# STM32L072xx register map
File version: 1.0
Registers are 32-bit, read-write, reset 0x0 unless marked. A register's access mark holds for its fields unless they carry their own. Offsets are from the block's base; [hi:lo] are bit positions.

## PWR — Power Control
Base 0x40007000
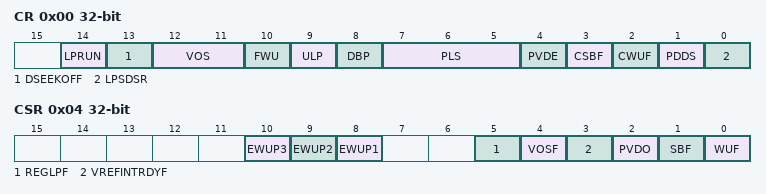
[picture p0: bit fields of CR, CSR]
0x00 CR — PWR power control register
  [14] LPRUN — Low power run mode
  [13] DSEEKOFF — Deep Sleep mode with EEPROM kept Off
  [12:11] VOS — VOS[1:0] bits (Voltage scaling range selection)
    1=SCALE1 (1.8V (range 1)); 2=SCALE2 (1.5V (range 2)); 3=SCALE3 (1.2V (range 3))
  [10] FWU — Fast wakeup
  [9] ULP — Ultra Low Power mode
  [8] DBP — Disable Backup Domain write protection
  [7:5] PLS — PLS[2:0] bits (PVD Level Selection)
    0=PVDLEVEL_0 (Voltage threshold detected by PVD 1.9 V); 1=PVDLEVEL_1 (Voltage threshold detected by PVD 2.1 V); 2=PVDLEVEL_2 (Voltage threshold detected by PVD 2.3 V); 3=PVDLEVEL_3 (Voltage threshold detected by PVD 2.5 V); 4=PVDLEVEL_4 (Voltage threshold detected by PVD 2.7 V); 5=PVDLEVEL_5 (Voltage threshold detected by PVD 2.9 V); 6=PVDLEVEL_6 (Voltage threshold detected by PVD 3.1 V); 7=PVDLEVEL_7 (External input analog voltage (Compare internally to VREFINT))
  [4] PVDE — Power Voltage Detector Enable
  [3] CSBF — Clear Standby Flag
  [2] CWUF — Clear Wakeup Flag
  [1] PDDS — Power Down Deepsleep
    0=STOP (Enter Stop mode when the CPU enters deepsleep); 1=STANDBY (Enter Standby mode when the CPU enters deepsleep)
  [0] LPSDSR — Low-power deepsleep/sleep/low power run
    0=MAIN (Voltage regulator in main mode during deepsleep/sleep/low-power run mode); 1=LOW_POWER (Voltage regulator in low-power mode during deepsleep/sleep/low-power run mode)
0x04 CSR — PWR power control/status register
  [10] EWUP3 — Enable WKUP pin 3
  [9] EWUP2 — Enable WKUP pin 2
  [8] EWUP1 — Enable WKUP pin 1
  [5] REGLPF — Regulator LP flag
  [4] VOSF — Voltage Scaling select flag
  [3] VREFINTRDYF — Internal voltage reference (VREFINT) ready flag
  [2] PVDO — PVD Output
  [1] SBF — Standby Flag
  [0] WUF — Wakeup Flag

## DAC — Digital to Analog Converter
Base 0x40007400
Same registers: DAC1 0x40007400 (alternate view of DAC)
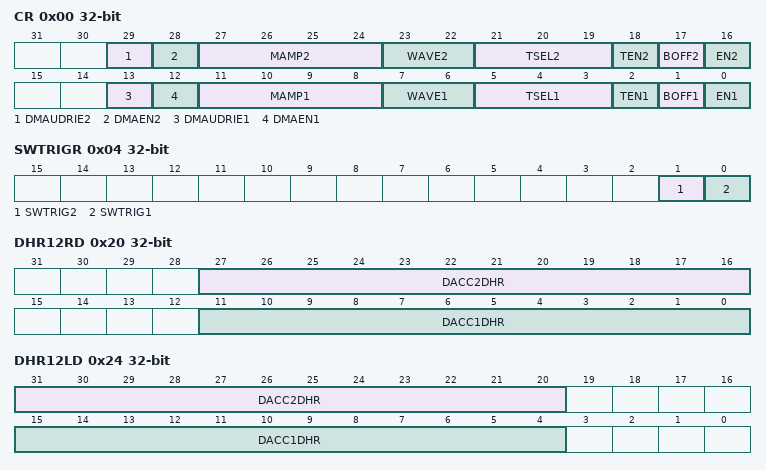
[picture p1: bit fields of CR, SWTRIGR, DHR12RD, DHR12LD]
0x00 CR — DAC control register
  [29] DMAUDRIE2 — DAC channel12DMA Underrun interrupt enable
  [28] DMAEN2 — DAC channel2 DMA enabled
  [27:24] MAMP2 — MAMP2[3:0] (DAC channel2 Mask/Amplitude selector)
  [23:22] WAVE2 — WAVE2[1:0] (DAC channel2 noise/triangle wave generation enable)
  [21:19] TSEL2 — TSEL2[2:0] (DAC channel2 Trigger selection)
  [18] TEN2 — DAC channel2 Trigger enable
  [17] BOFF2 — DAC channel2 output buffer disable
  [16] EN2 — DAC channel2 enable
  [13] DMAUDRIE1 — DAC channel1 DMA Underrun interrupt enable
  [12] DMAEN1 — DAC channel1 DMA enable
  [11:8] MAMP1 — MAMP1[3:0] (DAC channel1 Mask/Amplitude selector)
  [7:6] WAVE1 — WAVE1[1:0] (DAC channel1 noise/triangle wave generation enable)
  [5:3] TSEL1 — TSEL1[2:0] (DAC channel1 Trigger selection)
  [2] TEN1 — DAC channel1 Trigger enable
  [1] BOFF1 — DAC channel1 output buffer disable
  [0] EN1 — DAC channel1 enable
0x04 SWTRIGR — DAC software trigger register
  [1] SWTRIG2 — DAC channel2 software trigger
  [0] SWTRIG1 — DAC channel1 software trigger
0x08 DHR12R1 — DAC channel1 12-bit right-aligned data holding register
  [11:0] DACC1DHR — DAC channel1 12-bit Right aligned data
0x0C DHR12L1 — DAC channel1 12-bit left aligned data holding register
  [15:4] DACC1DHR — DAC channel1 12-bit Left aligned data
0x10 DHR8R1 — DAC channel1 8-bit right aligned data holding register
  [7:0] DACC1DHR — DAC channel1 8-bit Right aligned data
0x14 DHR12R2 — DAC channel2 12-bit right aligned data holding register
  [11:0] DACC2DHR — DAC channel2 12-bit Right aligned data
0x18 DHR12L2 — DAC channel2 12-bit left aligned data holding register
  [15:4] DACC2DHR — DAC channel2 12-bit Left aligned data
0x1C DHR8R2 — DAC channel2 8-bit right-aligned data holding register
  [7:0] DACC2DHR — DAC channel2 8-bit Right aligned data
0x20 DHR12RD — Dual DAC 12-bit right-aligned data holding register
  [27:16] DACC2DHR — DAC channel2 12-bit Right aligned data
  [11:0] DACC1DHR — DAC channel1 12-bit Right aligned data
0x24 DHR12LD — DUAL DAC 12-bit left aligned data holding register
  [31:20] DACC2DHR — DAC channel2 12-bit Left aligned data
  [15:4] DACC1DHR — DAC channel1 12-bit Left aligned data
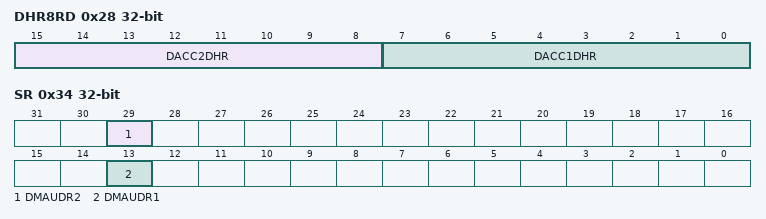
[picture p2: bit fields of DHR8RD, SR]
0x28 DHR8RD — DUAL DAC 8-bit right aligned data holding register
  [15:8] DACC2DHR — DAC channel2 8-bit Right aligned data
  [7:0] DACC1DHR — DAC channel1 8-bit Right aligned data
0x2C DOR1 — DAC channel1 data output register
  [11:0] DACC1DOR — DAC channel1 data output
0x30 DOR2 — DAC channel2 data output register
  [11:0] DACC2DOR — DAC channel2 data output
0x34 SR — DAC status register
  [29] DMAUDR2 — DAC channel2 DMA underrun flag
  [13] DMAUDR1 — DAC channel1 DMA underrun flag
